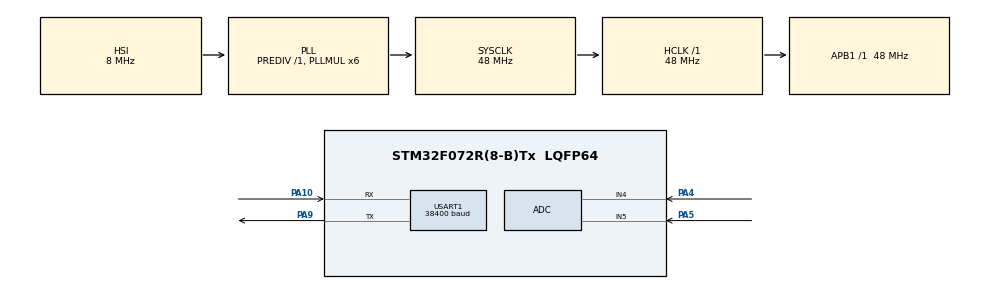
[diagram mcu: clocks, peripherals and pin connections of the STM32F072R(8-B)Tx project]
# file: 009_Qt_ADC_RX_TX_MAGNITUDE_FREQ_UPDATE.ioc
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ADC.ContinuousConvMode=ENABLE
ADC.DMAContinuousRequests=ENABLE
ADC.SamplingTime=ADC_SAMPLETIME_71CYCLES_5
ADC.ScanConvMode=ADC_SCAN_DIRECTION_FORWARD
Dma.ADC.0.Direction=DMA_PERIPH_TO_MEMORY
Dma.ADC.0.Instance=DMA1_Channel1
Dma.ADC.0.MemDataAlignment=DMA_MDATAALIGN_HALFWORD
Dma.ADC.0.MemInc=DMA_MINC_ENABLE
Dma.ADC.0.Mode=DMA_CIRCULAR
Dma.ADC.0.PeriphDataAlignment=DMA_PDATAALIGN_HALFWORD
Dma.ADC.0.PeriphInc=DMA_PINC_DISABLE
Dma.ADC.0.Priority=DMA_PRIORITY_LOW
Dma.Request0=ADC
Mcu.Family=STM32F0
Mcu.Name=STM32F072R(8-B)Tx
Mcu.Package=LQFP64
NVIC.ADC1_COMP_IRQn=true\:2\:0\:true\:false\:true\:true\:true\:true
NVIC.DMA1_Channel1_IRQn=true\:0\:0\:true\:false\:true\:false\:true\:true
NVIC.TIM6_DAC_IRQn=true\:0\:0\:false\:false\:true\:true\:true\:true
NVIC.USART1_IRQn=true\:1\:0\:true\:false\:true\:true\:true\:true
PA10.Mode=Asynchronous
PA10.Signal=USART1_RX
PA13.Mode=Serial_Wire
PA13.Signal=SYS_SWDIO
PA14.Mode=Serial_Wire
PA14.Signal=SYS_SWCLK
PA4.Mode=IN4
PA4.Signal=ADC_IN4
PA5.Mode=IN5
PA5.Signal=ADC_IN5
PA9.Mode=Asynchronous
PA9.Signal=USART1_TX
PF0-OSC_IN.Mode=HSE-External-Oscillator
PF0-OSC_IN.Signal=RCC_OSC_IN
PF1-OSC_OUT.Mode=HSE-External-Oscillator
PF1-OSC_OUT.Signal=RCC_OSC_OUT
ProjectManager.HeapSize=0x200
ProjectManager.StackSize=0x400
ProjectManager.TargetToolchain=STM32CubeIDE
RCC.AHBFreq_Value=48000000
RCC.APB1Freq_Value=48000000
RCC.APB1TimFreq_Value=48000000
RCC.HCLKFreq_Value=48000000
RCC.PLLMUL=RCC_PLL_MUL6
RCC.SYSCLKFreq_VALUE=48000000
RCC.SYSCLKSource=RCC_SYSCLKSOURCE_PLLCLK
TIM6.Period=47000
USART1.BaudRate=38400
USART1.VirtualMode-Asynchronous=VM_ASYNC
VP_TIM6_VS_ClockSourceINT.Mode=Enable_Timer
board=STM32F072B-DISCO

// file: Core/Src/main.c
/* USER CODE BEGIN Header */
/**
  ******************************************************************************
  * @file           : main.c
  * @brief          : Main program body
  ******************************************************************************
  * @attention
  *
  * Copyright (c) 2023 STMicroelectronics.
  * All rights reserved.
  *
  * This software is licensed under terms that can be found in the LICENSE file
  * in the root directory of this software component.
  * If no LICENSE file comes with this software, it is provided AS-IS.
  *
  ******************************************************************************
  */
/* USER CODE END Header */
#include "main.h"

/* USER CODE BEGIN Includes */
#include <stdio.h>
#include <string.h>
/* USER CODE END Includes */

ADC_HandleTypeDef hadc;
DMA_HandleTypeDef hdma_adc;

TIM_HandleTypeDef htim6;

UART_HandleTypeDef huart1;

/* USER CODE BEGIN PV */

#define ADC_MIN_VALUE 0
#define ADC_MAX_VALUE 4095
#define MAX_BUFFER_SIZE 50

#define NUMBER_ADC_CHANNEL 2
#define NUMBER_ADC_CHANNEL_AVERAGE_PER_CHANNEL 5

// For every adc channnel we read it 5 times and than find its average value for optimum adc reading
uint16_t ADC_DMA_BUFF[NUMBER_ADC_CHANNEL * NUMBER_ADC_CHANNEL_AVERAGE_PER_CHANNEL]={0};
uint16_t adcValue1, adcValue2;

uint8_t rx_buffer[MAX_BUFFER_SIZE];   // Rx buffer for uart receive takes the frequency, amplitude value from QT
uint8_t tx_buffer[MAX_BUFFER_SIZE];   // Tx buffer for uart transmission send x,y1,y2
uint8_t message[MAX_BUFFER_SIZE];     // Rx buffer is coppied here to prevent data loss from overwriting

uint8_t rx_index = 0;
uint8_t uart1RxBuffer[1];             // We read from the UART bit by bit then assign it to rx_buffer
volatile uint8_t timeoutCounter = 0;  // Timeout counter for rx interrupt callback function

volatile uint8_t magnitude = 1;	  // Magnitude value that is read from Rx
volatile float frequency = 1.0f;  // Frequency value that is read from Rx
float xData = 0.0f;
uint16_t y1Data, y2Data;  // After ADC value is mapped and magnified by the received constant

/* USER CODE END PV */

void SystemClock_Config(void);
static void MX_GPIO_Init(void);
static void MX_DMA_Init(void);
static void MX_TIM6_Init(void);
static void MX_USART1_UART_Init(void);
static void MX_ADC_Init(void);

/* USER CODE BEGIN 0 */

// This function is used to map the adc values within the specified boundaries
uint16_t map(uint16_t inputValue, uint16_t inputMin, uint16_t inputMax, uint16_t outputMin, uint16_t outputMax)
{
  return (magnitude * (inputValue - inputMin) * (outputMax - outputMin + 1) / (inputMax - inputMin) + outputMin);
}

// Return 1 if rx_buffer is empty
int isRxEmpty() {
	for (int i = 0; i < sizeof(rx_buffer); i++) {
	    if (rx_buffer[i] != 0) {
	        return 0;
	    }
	}
	return 1;
}

// If timerCounter is done, it means we didnt receive any signal for 7byte time long
// (9600 baudrate, 1/9600 bit/s = 104µs) then we reset the rx_buffer
void resetRx(void)
{
	rx_index = 0;
	timeoutCounter = 0;

	if(isRxEmpty() == 0) {
		for(int i = 0; i<MAX_BUFFER_SIZE; i++) {
			message[i] = rx_buffer[i];
		}
	}

	for(int i = 0; i<MAX_BUFFER_SIZE; i++)
		rx_buffer[i] = 0;
}

void HAL_UART_RxCpltCallback(UART_HandleTypeDef *huart)
{

  if ( huart->Instance == USART1 )
   {
	 timeoutCounter = 0;    // Reset the counter if we received data through uart
	 HAL_TIM_Base_Start_IT(&htim6);

	 HAL_UART_Receive_IT( &huart1, uart1RxBuffer, 1 );
	 rx_buffer[rx_index] = uart1RxBuffer[ 0 ];

	 // Coppies the rx to the message buffer so that when rx_buffer is overwritten its contents are kept
	 message[rx_index] = rx_buffer[rx_index];
	 rx_index++;
   }
}

// Timer interrupt callback for received data timeout
void HAL_TIM_PeriodElapsedCallback(TIM_HandleTypeDef *htim)
{
	if(htim->Instance == TIM6) {
    // 60 is for 7byte long time
		if(timeoutCounter <= 60 && rx_index < MAX_BUFFER_SIZE)
			timeoutCounter++;
		else
			resetRx();
	}
}

// Finds the average ADC reading for specified channel
uint16_t ADC_DMA_AVERAGE(int channel)
{
	uint32_t adc_sum;
	int i;

	adc_sum = 0;
	if(channel < NUMBER_ADC_CHANNEL )
	{
		for(i=0; i<NUMBER_ADC_CHANNEL_AVERAGE_PER_CHANNEL; i++)
			adc_sum += ADC_DMA_BUFF[channel+i*NUMBER_ADC_CHANNEL];
	}
	else
		return 1;

	return adc_sum/NUMBER_ADC_CHANNEL_AVERAGE_PER_CHANNEL;
}

void HAL_ADC_ConvCpltCallback(ADC_HandleTypeDef* hadc)
{
	adcValue1 = ADC_DMA_AVERAGE(0);
	adcValue2 = ADC_DMA_AVERAGE(1);
	y1Data = map(adcValue1, ADC_MIN_VALUE, ADC_MAX_VALUE, 0, 100);  // map the ADC between 0 and 100
	y2Data = map(adcValue2, ADC_MIN_VALUE, ADC_MAX_VALUE, 0, 100);  // map the ADC between 0 and 100
}

// The message is formatted as "timeConstant, magnitude"
// For example: 3, 5  --> Output: time steps become 0.3, and magnitude becomes 5 times larger
void Read_Message()
{
  // Read data is coppied to the specified variables
	sscanf((char*)message, "%f, %hu", &frequency, &magnitude);
}

/* USER CODE END 0 */

int main(void)
{

  /* MCU Configuration--------------------------------------------------------*/

  /* Reset of all peripherals, Initializes the Flash interface and the Systick. */
  HAL_Init();

  /* Configure the system clock */
  SystemClock_Config();

  /* Initialize all configured peripherals */
  MX_GPIO_Init();
  MX_DMA_Init();
  MX_TIM6_Init();
  MX_USART1_UART_Init();
  MX_ADC_Init();
  /* USER CODE BEGIN 2 */

  // Start DMA and Receive interrupt
  HAL_UART_Receive_IT( &huart1, uart1RxBuffer, 1 );
  HAL_ADC_Start_DMA(&hadc, (uint32_t *)ADC_DMA_BUFF, NUMBER_ADC_CHANNEL * NUMBER_ADC_CHANNEL_AVERAGE_PER_CHANNEL);

  /* USER CODE END 2 */

  /* Infinite loop */
  while (1)
  {

    /* USER CODE BEGIN 3 */
	  Read_Message();
	  xData += (1 / frequency);
	  HAL_UART_Transmit(&huart1, (uint8_t*)&tx_buffer, sprintf(tx_buffer, "%.2f, %d\n", xData, y1Data), HAL_MAX_DELAY);
	  HAL_Delay((int) (1000/frequency));
  }
  /* USER CODE END 3 */
}

void SystemClock_Config(void)
{
  RCC_OscInitTypeDef RCC_OscInitStruct = {0};
  RCC_ClkInitTypeDef RCC_ClkInitStruct = {0};
  RCC_PeriphCLKInitTypeDef PeriphClkInit = {0};

  /** Initializes the RCC Oscillators according to the specified parameters
  * in the RCC_OscInitTypeDef structure.
  */
  RCC_OscInitStruct.OscillatorType = RCC_OSCILLATORTYPE_HSI|RCC_OSCILLATORTYPE_HSI14;
  RCC_OscInitStruct.HSIState = RCC_HSI_ON;
  RCC_OscInitStruct.HSI14State = RCC_HSI14_ON;
  RCC_OscInitStruct.HSICalibrationValue = RCC_HSICALIBRATION_DEFAULT;
  RCC_OscInitStruct.HSI14CalibrationValue = 16;
  RCC_OscInitStruct.PLL.PLLState = RCC_PLL_ON;
  RCC_OscInitStruct.PLL.PLLSource = RCC_PLLSOURCE_HSI;
  RCC_OscInitStruct.PLL.PLLMUL = RCC_PLL_MUL6;
  RCC_OscInitStruct.PLL.PREDIV = RCC_PREDIV_DIV1;
  if (HAL_RCC_OscConfig(&RCC_OscInitStruct) != HAL_OK)
  {
    Error_Handler();
  }

  /** Initializes the CPU, AHB and APB buses clocks
  */
  RCC_ClkInitStruct.ClockType = RCC_CLOCKTYPE_HCLK|RCC_CLOCKTYPE_SYSCLK
                              |RCC_CLOCKTYPE_PCLK1;
  RCC_ClkInitStruct.SYSCLKSource = RCC_SYSCLKSOURCE_PLLCLK;
  RCC_ClkInitStruct.AHBCLKDivider = RCC_SYSCLK_DIV1;
  RCC_ClkInitStruct.APB1CLKDivider = RCC_HCLK_DIV1;

  if (HAL_RCC_ClockConfig(&RCC_ClkInitStruct, FLASH_LATENCY_1) != HAL_OK)
  {
    Error_Handler();
  }
  PeriphClkInit.PeriphClockSelection = RCC_PERIPHCLK_USART1;
  PeriphClkInit.Usart1ClockSelection = RCC_USART1CLKSOURCE_PCLK1;
  if (HAL_RCCEx_PeriphCLKConfig(&PeriphClkInit) != HAL_OK)
  {
    Error_Handler();
  }
}

static void MX_ADC_Init(void)
{

  ADC_ChannelConfTypeDef sConfig = {0};

  /** Configure the global features of the ADC (Clock, Resolution, Data Alignment and number of conversion)
  */
  hadc.Instance = ADC1;
  hadc.Init.ClockPrescaler = ADC_CLOCK_ASYNC_DIV1;
  hadc.Init.Resolution = ADC_RESOLUTION_12B;
  hadc.Init.DataAlign = ADC_DATAALIGN_RIGHT;
  hadc.Init.ScanConvMode = ADC_SCAN_DIRECTION_FORWARD;
  hadc.Init.EOCSelection = ADC_EOC_SINGLE_CONV;
  hadc.Init.LowPowerAutoWait = DISABLE;
  hadc.Init.LowPowerAutoPowerOff = DISABLE;
  hadc.Init.ContinuousConvMode = ENABLE;
  hadc.Init.DiscontinuousConvMode = DISABLE;
  hadc.Init.ExternalTrigConv = ADC_SOFTWARE_START;
  hadc.Init.ExternalTrigConvEdge = ADC_EXTERNALTRIGCONVEDGE_NONE;
  hadc.Init.DMAContinuousRequests = ENABLE;
  hadc.Init.Overrun = ADC_OVR_DATA_PRESERVED;
  if (HAL_ADC_Init(&hadc) != HAL_OK)
  {
    Error_Handler();
  }

  /** Configure for the selected ADC regular channel to be converted.
  */
  sConfig.Channel = ADC_CHANNEL_4;
  sConfig.Rank = ADC_RANK_CHANNEL_NUMBER;
  sConfig.SamplingTime = ADC_SAMPLETIME_239CYCLES_5;
  if (HAL_ADC_ConfigChannel(&hadc, &sConfig) != HAL_OK)
  {
    Error_Handler();
  }

  /** Configure for the selected ADC regular channel to be converted.
  */
  sConfig.Channel = ADC_CHANNEL_5;
  if (HAL_ADC_ConfigChannel(&hadc, &sConfig) != HAL_OK)
  {
    Error_Handler();
  }

}

static void MX_TIM6_Init(void)
{

  TIM_MasterConfigTypeDef sMasterConfig = {0};

  htim6.Instance = TIM6;
  htim6.Init.Prescaler = 0;
  htim6.Init.CounterMode = TIM_COUNTERMODE_UP;
  htim6.Init.Period = 47000;
  htim6.Init.AutoReloadPreload = TIM_AUTORELOAD_PRELOAD_DISABLE;
  if (HAL_TIM_Base_Init(&htim6) != HAL_OK)
  {
    Error_Handler();
  }
  sMasterConfig.MasterOutputTrigger = TIM_TRGO_RESET;
  sMasterConfig.MasterSlaveMode = TIM_MASTERSLAVEMODE_DISABLE;
  if (HAL_TIMEx_MasterConfigSynchronization(&htim6, &sMasterConfig) != HAL_OK)
  {
    Error_Handler();
  }

}

static void MX_USART1_UART_Init(void)
{

  huart1.Instance = USART1;
  huart1.Init.BaudRate = 38400;
  huart1.Init.WordLength = UART_WORDLENGTH_8B;
  huart1.Init.StopBits = UART_STOPBITS_1;
  huart1.Init.Parity = UART_PARITY_NONE;
  huart1.Init.Mode = UART_MODE_TX_RX;
  huart1.Init.HwFlowCtl = UART_HWCONTROL_NONE;
  huart1.Init.OverSampling = UART_OVERSAMPLING_16;
  huart1.Init.OneBitSampling = UART_ONE_BIT_SAMPLE_DISABLE;
  huart1.AdvancedInit.AdvFeatureInit = UART_ADVFEATURE_NO_INIT;
  if (HAL_UART_Init(&huart1) != HAL_OK)
  {
    Error_Handler();
  }
  /* USER CODE BEGIN USART1_Init 2 */
  HAL_NVIC_SetPriority(USART1_IRQn, 3, 0);
  HAL_NVIC_EnableIRQ(USART1_IRQn);
  /* USER CODE END USART1_Init 2 */

}

static void MX_DMA_Init(void)
{

  /* DMA controller clock enable */
  __HAL_RCC_DMA1_CLK_ENABLE();

  /* DMA interrupt init */
  /* DMA1_Channel1_IRQn interrupt configuration */
  HAL_NVIC_SetPriority(DMA1_Channel1_IRQn, 0, 0);
  HAL_NVIC_EnableIRQ(DMA1_Channel1_IRQn);

}

static void MX_GPIO_Init(void)
{
  GPIO_InitTypeDef GPIO_InitStruct = {0};

  /* GPIO Ports Clock Enable */
  __HAL_RCC_GPIOF_CLK_ENABLE();
  __HAL_RCC_GPIOA_CLK_ENABLE();
  __HAL_RCC_GPIOC_CLK_ENABLE();

  /*Configure GPIO pin Output Level */
  HAL_GPIO_WritePin(GPIOC, GPIO_PIN_9, GPIO_PIN_RESET);

  /*Configure GPIO pin : PC9 */
  GPIO_InitStruct.Pin = GPIO_PIN_9;
  GPIO_InitStruct.Mode = GPIO_MODE_OUTPUT_PP;
  GPIO_InitStruct.Pull = GPIO_NOPULL;
  GPIO_InitStruct.Speed = GPIO_SPEED_FREQ_LOW;
  HAL_GPIO_Init(GPIOC, &GPIO_InitStruct);

}

void Error_Handler(void)
{
  __disable_irq();
  while (1)
  {
  }
}
